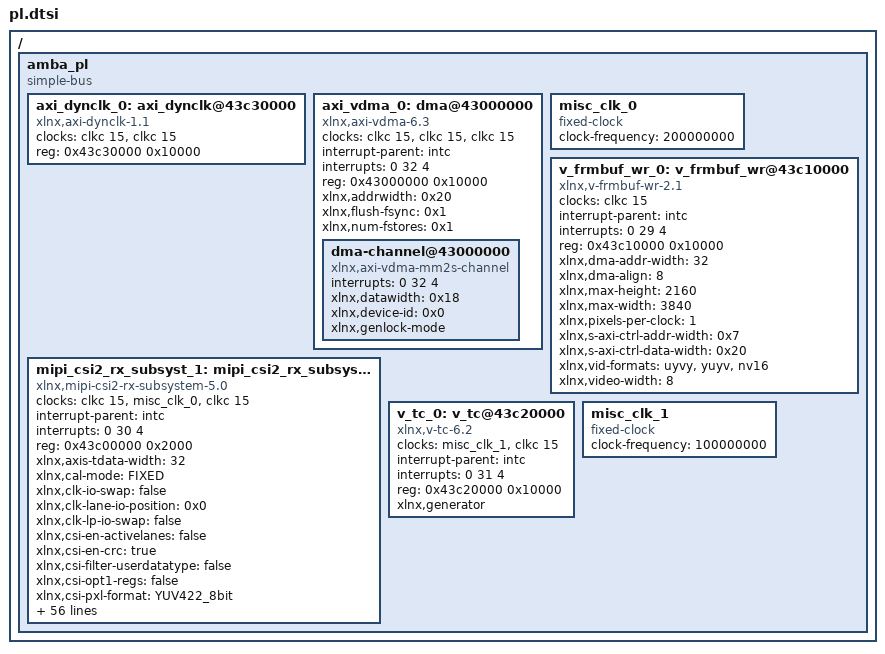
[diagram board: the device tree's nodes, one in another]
/*
 * CAUTION: This file is automatically generated by Xilinx.
 * Version:  
 * Today is: Thu Nov  5 03:04:25 2020
 */


/ {
	amba_pl: amba_pl {
		#address-cells = <1>;
		#size-cells = <1>;
		compatible = "simple-bus";
		ranges ;
		axi_dynclk_0: axi_dynclk@43c30000 {
			clock-names = "REF_CLK_I", "s_axi_lite_aclk";
			clocks = <&clkc 15>, <&clkc 15>;
			compatible = "xlnx,axi-dynclk-1.1";
			reg = <0x43c30000 0x10000>;
		};
		axi_vdma_0: dma@43000000 {
			#dma-cells = <1>;
			clock-names = "s_axi_lite_aclk", "m_axi_mm2s_aclk", "m_axis_mm2s_aclk";
			clocks = <&clkc 15>, <&clkc 15>, <&clkc 15>;
			compatible = "xlnx,axi-vdma-6.3", "xlnx,axi-vdma-1.00.a";
			interrupt-names = "mm2s_introut";
			interrupt-parent = <&intc>;
			interrupts = <0 32 4>;
			reg = <0x43000000 0x10000>;
			xlnx,addrwidth = <0x20>;
			xlnx,flush-fsync = <0x1>;
			xlnx,num-fstores = <0x1>;
			dma-channel@43000000 {
				compatible = "xlnx,axi-vdma-mm2s-channel";
				interrupts = <0 32 4>;
				xlnx,datawidth = <0x18>;
				xlnx,device-id = <0x0>;
				xlnx,genlock-mode ;
			};
		};
		mipi_csi2_rx_subsyst_1: mipi_csi2_rx_subsystem@43c00000 {
			clock-names = "lite_aclk", "dphy_clk_200M", "video_aclk";
			clocks = <&clkc 15>, <&misc_clk_0>, <&clkc 15>;
			compatible = "xlnx,mipi-csi2-rx-subsystem-5.0";
			interrupt-names = "csirxss_csi_irq";
			interrupt-parent = <&intc>;
			interrupts = <0 30 4>;
			reg = <0x43c00000 0x2000>;
			xlnx,axis-tdata-width = <32>;
			xlnx,cal-mode = "FIXED";
			xlnx,clk-io-swap = "false";
			xlnx,clk-lane-io-position = <0x0>;
			xlnx,clk-lp-io-swap = "false";
			xlnx,csi-en-activelanes = "false";
			xlnx,csi-en-crc = "true";
			xlnx,csi-filter-userdatatype = "false";
			xlnx,csi-opt1-regs = "false";
			xlnx,csi-pxl-format = "YUV422_8bit";
			xlnx,csi2rx-dbg = <0x0>;
			xlnx,data-lane0-io-position = <0x2>;
			xlnx,data-lane1-io-position = <0x4>;
			xlnx,data-lane2-io-position = <0x6>;
			xlnx,data-lane3-io-position = <0x8>;
			xlnx,dl0-io-swap = "false";
			xlnx,dl0-lp-io-swap = "false";
			xlnx,dl1-io-swap = "false";
			xlnx,dl1-lp-io-swap = "false";
			xlnx,dl2-io-swap = "false";
			xlnx,dl2-lp-io-swap = "false";
			xlnx,dl3-io-swap = "false";
			xlnx,dl3-lp-io-swap = "false";
			xlnx,dphy-lanes = <0x2>;
			xlnx,dphy-mode = "SLAVE";
			xlnx,dphy-present ;
			xlnx,en-bg0-pin0 = "false";
			xlnx,en-bg0-pin6 = "false";
			xlnx,en-bg1-pin0 = "false";
			xlnx,en-bg1-pin6 = "false";
			xlnx,en-bg2-pin0 = "false";
			xlnx,en-bg2-pin6 = "false";
			xlnx,en-bg3-pin0 = "false";
			xlnx,en-bg3-pin6 = "false";
			xlnx,en-clk300m = "false";
			xlnx,en-cnts-byte-clk = "false";
			xlnx,en-csi-v2-0 = "false";
			xlnx,en-exdesigns = "false";
			xlnx,en-timeout-regs = "false";
			xlnx,en-vcx = "false";
			xlnx,esc-timeout = <0x6400>;
			xlnx,exdes-board = "ZCU102";
			xlnx,exdes-config = "MIPI_Video_Pipe_Camera_to_Display";
			xlnx,exdes-fmc = "LI-IMX274MIPI-FMC V1.0 Single Sensor";
			xlnx,fifo-rd-en-control = "true";
			xlnx,hs-line-rate = <0x320>;
			xlnx,hs-settle-ns = <0x93>;
			xlnx,hs-timeout = <0x10005>;
			xlnx,idly-group-name = "mipi_csi2rx_idly_group";
			xlnx,idly-tap = <0xa>;
			xlnx,init = <0x186a0>;
			xlnx,is-7series = "true";
			xlnx,is-versal = "false";
			xlnx,lprx-disable-extport = <0x0>;
			xlnx,max-lanes = <2>;
			xlnx,mipi-slv-int = <0x0>;
			xlnx,ooc-vid-clk = "6.666";
			xlnx,ppc = <1>;
			xlnx,rcve-alt-deskew-seq = "false";
			xlnx,rcve-deskew-seq = "false";
			xlnx,share-idlyctrl = "true";
			xlnx,stretch-line-rate = <0xdac>;
			xlnx,vc = <4>;
			xlnx,vfb ;
		};
		misc_clk_0: misc_clk_0 {
			#clock-cells = <0>;
			clock-frequency = <200000000>;
			compatible = "fixed-clock";
		};
		v_frmbuf_wr_0: v_frmbuf_wr@43c10000 {
			#dma-cells = <1>;
			clock-names = "ap_clk";
			clocks = <&clkc 15>;
			compatible = "xlnx,v-frmbuf-wr-2.1", "xlnx,axi-frmbuf-wr-v2.1";
			interrupt-names = "interrupt";
			interrupt-parent = <&intc>;
			interrupts = <0 29 4>;
			reg = <0x43c10000 0x10000>;
			xlnx,dma-addr-width = <32>;
			xlnx,dma-align = <8>;
			xlnx,max-height = <2160>;
			xlnx,max-width = <3840>;
			xlnx,pixels-per-clock = <1>;
			xlnx,s-axi-ctrl-addr-width = <0x7>;
			xlnx,s-axi-ctrl-data-width = <0x20>;
			xlnx,vid-formats = "uyvy", "yuyv", "nv16";
			xlnx,video-width = <8>;
		};
		v_tc_0: v_tc@43c20000 {
			clock-names = "clk", "s_axi_aclk";
			clocks = <&misc_clk_1>, <&clkc 15>;
			compatible = "xlnx,v-tc-6.2", "xlnx,v-tc-6.1";
			interrupt-names = "irq";
			interrupt-parent = <&intc>;
			interrupts = <0 31 4>;
			reg = <0x43c20000 0x10000>;
			xlnx,generator ;
		};
		misc_clk_1: misc_clk_1 {
			#clock-cells = <0>;
			clock-frequency = <100000000>;
			compatible = "fixed-clock";
		};
	};
};
